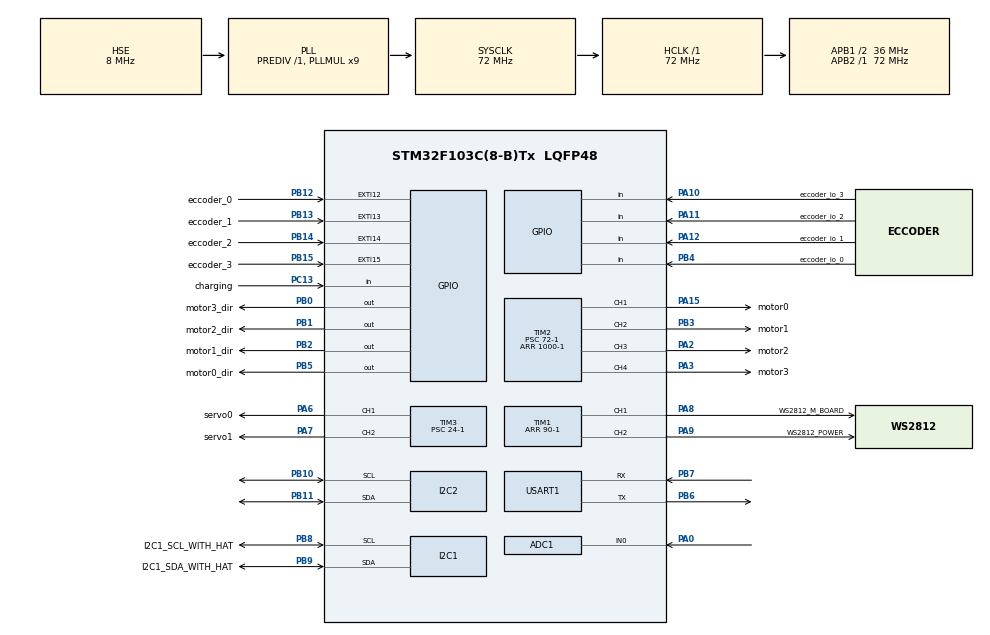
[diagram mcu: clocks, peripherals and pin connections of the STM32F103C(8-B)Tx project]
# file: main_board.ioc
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ADC1.Channel-0\#ChannelRegularConversion=ADC_CHANNEL_0
ADC1.ContinuousConvMode=ENABLE
ADC1.NbrOfConversionFlag=1
ADC1.Rank-0\#ChannelRegularConversion=1
ADC1.SamplingTime-0\#ChannelRegularConversion=ADC_SAMPLETIME_239CYCLES_5
ADC1.master=1
Dma.ADC1.0.Direction=DMA_PERIPH_TO_MEMORY
Dma.ADC1.0.Instance=DMA1_Channel1
Dma.ADC1.0.MemDataAlignment=DMA_MDATAALIGN_HALFWORD
Dma.ADC1.0.MemInc=DMA_MINC_ENABLE
Dma.ADC1.0.Mode=DMA_CIRCULAR
Dma.ADC1.0.PeriphDataAlignment=DMA_PDATAALIGN_HALFWORD
Dma.ADC1.0.PeriphInc=DMA_PINC_DISABLE
Dma.ADC1.0.Priority=DMA_PRIORITY_LOW
Dma.Request0=ADC1
Dma.Request1=TIM1_CH1
Dma.Request2=TIM1_CH2
Dma.Request3=USART1_RX
Dma.TIM1_CH1.1.Direction=DMA_MEMORY_TO_PERIPH
Dma.TIM1_CH1.1.Instance=DMA1_Channel2
Dma.TIM1_CH1.1.MemDataAlignment=DMA_MDATAALIGN_BYTE
Dma.TIM1_CH1.1.MemInc=DMA_MINC_ENABLE
Dma.TIM1_CH1.1.Mode=DMA_CIRCULAR
Dma.TIM1_CH1.1.PeriphDataAlignment=DMA_PDATAALIGN_HALFWORD
Dma.TIM1_CH1.1.PeriphInc=DMA_PINC_DISABLE
Dma.TIM1_CH1.1.Priority=DMA_PRIORITY_LOW
Dma.TIM1_CH2.2.Direction=DMA_MEMORY_TO_PERIPH
Dma.TIM1_CH2.2.Instance=DMA1_Channel3
Dma.TIM1_CH2.2.MemDataAlignment=DMA_MDATAALIGN_BYTE
Dma.TIM1_CH2.2.MemInc=DMA_MINC_ENABLE
Dma.TIM1_CH2.2.Mode=DMA_CIRCULAR
Dma.TIM1_CH2.2.PeriphDataAlignment=DMA_PDATAALIGN_HALFWORD
Dma.TIM1_CH2.2.PeriphInc=DMA_PINC_DISABLE
Dma.TIM1_CH2.2.Priority=DMA_PRIORITY_LOW
Dma.USART1_RX.3.Direction=DMA_PERIPH_TO_MEMORY
Dma.USART1_RX.3.Instance=DMA1_Channel5
Dma.USART1_RX.3.MemDataAlignment=DMA_MDATAALIGN_BYTE
Dma.USART1_RX.3.MemInc=DMA_MINC_ENABLE
Dma.USART1_RX.3.Mode=DMA_CIRCULAR
Dma.USART1_RX.3.PeriphDataAlignment=DMA_PDATAALIGN_BYTE
Dma.USART1_RX.3.PeriphInc=DMA_PINC_DISABLE
Dma.USART1_RX.3.Priority=DMA_PRIORITY_LOW
I2C1.OwnAddress=0x0F
Mcu.Family=STM32F1
Mcu.Name=STM32F103C(8-B)Tx
Mcu.Package=LQFP48
NVIC.DMA1_Channel5_IRQn=true\:0\:0\:false\:false\:true\:true\:true\:true
NVIC.EXTI15_10_IRQn=true\:0\:0\:false\:false\:true\:true\:true\:true
NVIC.I2C1_ER_IRQn=true\:1\:0\:true\:false\:true\:true\:true\:true
NVIC.I2C1_EV_IRQn=true\:1\:0\:true\:false\:true\:true\:true\:true
NVIC.PriorityGroup=NVIC_PRIORITYGROUP_4
NVIC.USART1_IRQn=true\:0\:0\:false\:false\:true\:true\:true\:true
PA0-WKUP.Signal=ADCx_IN0
PA10.GPIO_Label=eccoder_io_3
PA10.GPIO_PuPd=GPIO_PULLUP
PA10.Signal=GPIO_Input
PA11.GPIO_Label=eccoder_io_2
PA11.GPIO_PuPd=GPIO_PULLUP
PA11.Signal=GPIO_Input
PA12.GPIO_Label=eccoder_io_1
PA12.GPIO_PuPd=GPIO_PULLUP
PA12.Signal=GPIO_Input
PA13.Mode=Serial_Wire
PA13.Signal=SYS_JTMS-SWDIO
PA14.Mode=Serial_Wire
PA14.Signal=SYS_JTCK-SWCLK
PA15.GPIO_Label=motor0
PA15.Signal=S_TIM2_CH1_ETR
PA2.GPIO_Label=motor2
PA2.Signal=S_TIM2_CH3
PA3.GPIO_Label=motor3
PA3.Signal=S_TIM2_CH4
PA6.GPIO_Label=servo0
PA6.Signal=S_TIM3_CH1
PA7.GPIO_Label=servo1
PA7.Signal=S_TIM3_CH2
PA8.GPIO_Label=WS2812_M_BOARD
PA8.GPIO_Speed=GPIO_SPEED_FREQ_HIGH
PA8.Signal=S_TIM1_CH1
PA9.GPIO_Label=WS2812_POWER
PA9.GPIO_Speed=GPIO_SPEED_FREQ_HIGH
PA9.Signal=S_TIM1_CH2
PB0.GPIO_Label=motor3_dir
PB0.Signal=GPIO_Output
PB1.GPIO_Label=motor2_dir
PB1.Signal=GPIO_Output
PB10.Mode=I2C
PB10.Signal=I2C2_SCL
PB11.Mode=I2C
PB11.Signal=I2C2_SDA
PB12.GPIO_Label=eccoder_0
PB12.GPIO_PuPd=GPIO_PULLUP
PB12.Signal=GPXTI12
PB13.GPIO_Label=eccoder_1
PB13.GPIO_PuPd=GPIO_PULLUP
PB13.Signal=GPXTI13
PB14.GPIO_Label=eccoder_2
PB14.GPIO_PuPd=GPIO_PULLUP
PB14.Signal=GPXTI14
PB15.GPIO_Label=eccoder_3
PB15.GPIO_PuPd=GPIO_PULLUP
PB15.Signal=GPXTI15
PB2.GPIO_Label=motor1_dir
PB2.Signal=GPIO_Output
PB3.GPIO_Label=motor1
PB3.Signal=S_TIM2_CH2
PB4.GPIO_Label=eccoder_io_0
PB4.GPIO_PuPd=GPIO_PULLUP
PB4.Signal=GPIO_Input
PB5.GPIO_Label=motor0_dir
PB5.Signal=GPIO_Output
PB6.Mode=Asynchronous
PB6.Signal=USART1_TX
PB7.Mode=Asynchronous
PB7.Signal=USART1_RX
PB8.GPIO_Label=I2C1_SCL_WITH_HAT
PB8.Mode=I2C
PB8.Signal=I2C1_SCL
PB9.GPIO_Label=I2C1_SDA_WITH_HAT
PB9.Mode=I2C
PB9.Signal=I2C1_SDA
PC13-TAMPER-RTC.GPIO_Label=charging
PC13-TAMPER-RTC.GPIO_PuPd=GPIO_PULLUP
PC13-TAMPER-RTC.Signal=GPIO_Input
PC14-OSC32_IN.Mode=LSE-External-Oscillator
PC14-OSC32_IN.Signal=RCC_OSC32_IN
PC15-OSC32_OUT.Mode=LSE-External-Oscillator
PC15-OSC32_OUT.Signal=RCC_OSC32_OUT
PD0-OSC_IN.Mode=HSE-External-Oscillator
PD0-OSC_IN.Signal=RCC_OSC_IN
PD1-OSC_OUT.Mode=HSE-External-Oscillator
PD1-OSC_OUT.Signal=RCC_OSC_OUT
ProjectManager.HeapSize=0x1C00
ProjectManager.StackSize=0x400
ProjectManager.TargetToolchain=MDK-ARM V5.32
RCC.ADCPresc=RCC_ADCPCLK2_DIV6
RCC.AHBFreq_Value=72000000
RCC.APB1CLKDivider=RCC_HCLK_DIV2
RCC.APB1Freq_Value=36000000
RCC.APB1TimFreq_Value=72000000
RCC.APB2Freq_Value=72000000
RCC.APB2TimFreq_Value=72000000
RCC.HCLKFreq_Value=72000000
RCC.PLLMUL=RCC_PLL_MUL9
RCC.PLLSourceVirtual=RCC_PLLSOURCE_HSE
RCC.RTCClockSelection=RCC_RTCCLKSOURCE_LSE
RCC.SYSCLKFreq_VALUE=72000000
RCC.SYSCLKSource=RCC_SYSCLKSOURCE_PLLCLK
RCC.USBFreq_Value=72000000
RTC.AsynchPrediv=RTC_AUTO_1_SECOND
RTC.AutoPrediv=RTC_AUTO_1_SECOND
SH.ADCx_IN0.0=ADC1_IN0,IN0
SH.S_TIM1_CH1.0=TIM1_CH1,PWM Generation1 CH1
SH.S_TIM1_CH2.0=TIM1_CH2,PWM Generation2 CH2
SH.S_TIM2_CH1_ETR.0=TIM2_CH1,PWM Generation1 CH1
SH.S_TIM2_CH2.0=TIM2_CH2,PWM Generation2 CH2
SH.S_TIM2_CH3.0=TIM2_CH3,PWM Generation3 CH3
SH.S_TIM2_CH4.0=TIM2_CH4,PWM Generation4 CH4
SH.S_TIM3_CH1.0=TIM3_CH1,PWM Generation1 CH1
SH.S_TIM3_CH2.0=TIM3_CH2,PWM Generation2 CH2
TIM1.Channel-PWM\ Generation1\ CH1=TIM_CHANNEL_1
TIM1.Channel-PWM\ Generation2\ CH2=TIM_CHANNEL_2
TIM1.Period=90-1
TIM2.Channel-PWM\ Generation1\ CH1=TIM_CHANNEL_1
TIM2.Channel-PWM\ Generation2\ CH2=TIM_CHANNEL_2
TIM2.Channel-PWM\ Generation3\ CH3=TIM_CHANNEL_3
TIM2.Channel-PWM\ Generation4\ CH4=TIM_CHANNEL_4
TIM2.Period=1000-1
TIM2.Prescaler=72-1
TIM3.Channel-PWM\ Generation1\ CH1=TIM_CHANNEL_1
TIM3.Channel-PWM\ Generation2\ CH2=TIM_CHANNEL_2
TIM3.Prescaler=24-1
USART1.VirtualMode=VM_ASYNC
VP_RTC_VS_RTC_Activate.Mode=RTC_Enabled
VP_RTC_VS_RTC_Calendar.Mode=RTC_Calendar
board=custom

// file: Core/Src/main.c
/* USER CODE BEGIN Header */
/**
  ******************************************************************************
  * @file           : main.c
  * @brief          : Main program body
  ******************************************************************************
  * @attention
  *
  * Copyright (c) 2025 STMicroelectronics.
  * All rights reserved.
  *
  * This software is licensed under terms that can be found in the LICENSE file
  * in the root directory of this software component.
  * If no LICENSE file comes with this software, it is provided AS-IS.
  *
  ******************************************************************************
  */
/* USER CODE END Header */
#include "main.h"
#include "adc.h"
#include "dma.h"
#include "i2c.h"
#include "rtc.h"
#include "tim.h"
#include "usart.h"
#include "gpio.h"

/* USER CODE BEGIN Includes */
#include "myMain.h"
/* USER CODE END Includes */

void SystemClock_Config(void);

int main(void)
{

  /* MCU Configuration--------------------------------------------------------*/

  /* Reset of all peripherals, Initializes the Flash interface and the Systick. */
  HAL_Init();

  /* Configure the system clock */
  SystemClock_Config();

  __disable_irq();

  /* Initialize all configured peripherals */
  MX_GPIO_Init();
  MX_DMA_Init();
  MX_ADC1_Init();
  MX_USART1_UART_Init();
  MX_TIM1_Init();
  MX_I2C1_Init();
  MX_TIM2_Init();
  MX_TIM3_Init();
  MX_RTC_Init();
  MX_I2C2_Init();
  /* USER CODE BEGIN 2 */

  setup();
  __enable_irq();

  /* USER CODE END 2 */

  /* Infinite loop */
  /* USER CODE BEGIN WHILE */
  while (1)
  {
    loop();
    /* USER CODE END WHILE */

  }
}

void SystemClock_Config(void)
{
  RCC_OscInitTypeDef RCC_OscInitStruct = {0};
  RCC_ClkInitTypeDef RCC_ClkInitStruct = {0};
  RCC_PeriphCLKInitTypeDef PeriphClkInit = {0};

  /** Initializes the RCC Oscillators according to the specified parameters
  * in the RCC_OscInitTypeDef structure.
  */
  RCC_OscInitStruct.OscillatorType = RCC_OSCILLATORTYPE_HSE|RCC_OSCILLATORTYPE_LSE;
  RCC_OscInitStruct.HSEState = RCC_HSE_ON;
  RCC_OscInitStruct.HSEPredivValue = RCC_HSE_PREDIV_DIV1;
  RCC_OscInitStruct.LSEState = RCC_LSE_ON;
  RCC_OscInitStruct.HSIState = RCC_HSI_ON;
  RCC_OscInitStruct.PLL.PLLState = RCC_PLL_ON;
  RCC_OscInitStruct.PLL.PLLSource = RCC_PLLSOURCE_HSE;
  RCC_OscInitStruct.PLL.PLLMUL = RCC_PLL_MUL9;
  if (HAL_RCC_OscConfig(&RCC_OscInitStruct) != HAL_OK)
  {
    Error_Handler();
  }

  /** Initializes the CPU, AHB and APB buses clocks
  */
  RCC_ClkInitStruct.ClockType = RCC_CLOCKTYPE_HCLK|RCC_CLOCKTYPE_SYSCLK
                              |RCC_CLOCKTYPE_PCLK1|RCC_CLOCKTYPE_PCLK2;
  RCC_ClkInitStruct.SYSCLKSource = RCC_SYSCLKSOURCE_PLLCLK;
  RCC_ClkInitStruct.AHBCLKDivider = RCC_SYSCLK_DIV1;
  RCC_ClkInitStruct.APB1CLKDivider = RCC_HCLK_DIV2;
  RCC_ClkInitStruct.APB2CLKDivider = RCC_HCLK_DIV1;

  if (HAL_RCC_ClockConfig(&RCC_ClkInitStruct, FLASH_LATENCY_2) != HAL_OK)
  {
    Error_Handler();
  }
  PeriphClkInit.PeriphClockSelection = RCC_PERIPHCLK_RTC|RCC_PERIPHCLK_ADC;
  PeriphClkInit.RTCClockSelection = RCC_RTCCLKSOURCE_LSE;
  PeriphClkInit.AdcClockSelection = RCC_ADCPCLK2_DIV6;
  if (HAL_RCCEx_PeriphCLKConfig(&PeriphClkInit) != HAL_OK)
  {
    Error_Handler();
  }
}

void Error_Handler(void)
{
  __disable_irq();
  while (1)
  {
  }
}
